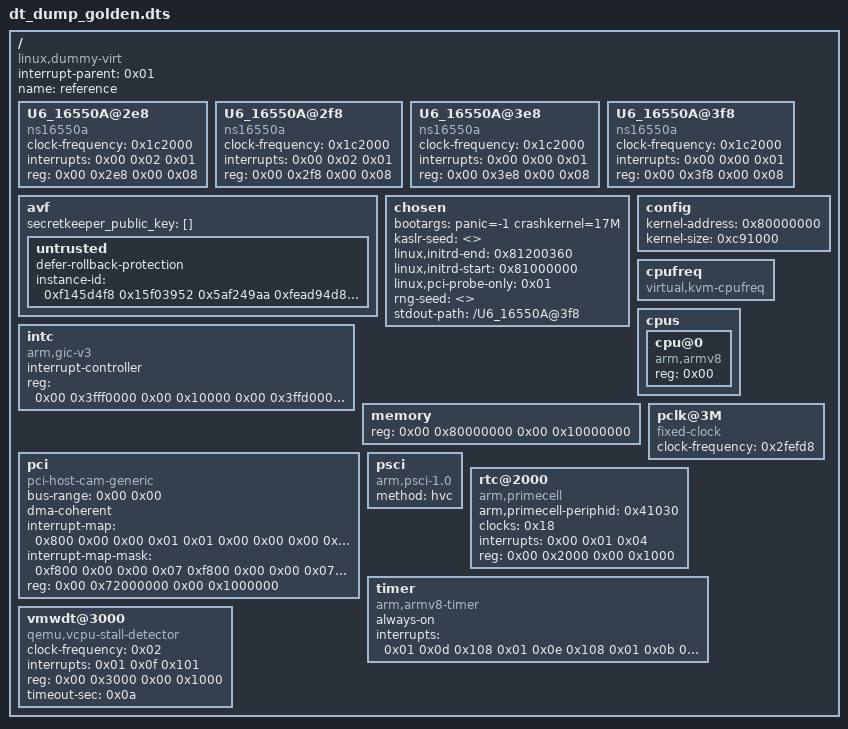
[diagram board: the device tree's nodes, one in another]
/dts-v1/;

/ {
        #address-cells = <0x02>;
        #size-cells = <0x02>;
        compatible = "linux,dummy-virt";
        interrupt-parent = <0x01>;
        name = "reference";

        U6_16550A@2e8 {
                clock-frequency = <0x1c2000>;
                compatible = "ns16550a";
                interrupts = <0x00 0x02 0x01>;
                reg = <0x00 0x2e8 0x00 0x08>;
        };

        U6_16550A@2f8 {
                clock-frequency = <0x1c2000>;
                compatible = "ns16550a";
                interrupts = <0x00 0x02 0x01>;
                reg = <0x00 0x2f8 0x00 0x08>;
        };

        U6_16550A@3e8 {
                clock-frequency = <0x1c2000>;
                compatible = "ns16550a";
                interrupts = <0x00 0x00 0x01>;
                reg = <0x00 0x3e8 0x00 0x08>;
        };

        U6_16550A@3f8 {
                clock-frequency = <0x1c2000>;
                compatible = "ns16550a";
                interrupts = <0x00 0x00 0x01>;
                reg = <0x00 0x3f8 0x00 0x08>;
        };

        __symbols__ {
                intc = "/intc";
        };

        avf {
                secretkeeper_public_key = [];

                untrusted {
                        defer-rollback-protection;
                        instance-id = <0xf145d4f8 0x15f03952 0x5af249aa 0xfead94d8 0xb9f05746 0xd9163f48 0x7251b67b 0xe117409e 0x2b14dfa5 0xcaa8caf7 0x14176d2d 0xf88cc94b 0xeed4a59d 0x9a2d8fe5 0x5ac590f1 0xbb6c96f5>;
                };
        };

        chosen {
                bootargs = "panic=-1 crashkernel=17M";
                kaslr-seed = <>;
                linux,initrd-end = <0x81200360>;
                linux,initrd-start = <0x81000000>;
                linux,pci-probe-only = <0x01>;
                rng-seed = <>;
                stdout-path = "/U6_16550A@3f8";
        };

        config {
                kernel-address = <0x80000000>;
                kernel-size = <0xc91000>;
        };

        cpufreq {
                compatible = "virtual,kvm-cpufreq";
        };

        cpus {
                #address-cells = <0x01>;
                #size-cells = <0x00>;

                cpu@0 {
                        compatible = "arm,armv8";
                        device_type = "cpu";
                        phandle = <0x100>;
                        reg = <0x00>;
                };
        };

        intc {
                #address-cells = <0x02>;
                #interrupt-cells = <0x03>;
                #size-cells = <0x02>;
                compatible = "arm,gic-v3";
                interrupt-controller;
                phandle = <0x01>;
                reg = <0x00 0x3fff0000 0x00 0x10000 0x00 0x3ffd0000 0x00 0x20000>;
        };

        memory {
                device_type = "memory";
                reg = <0x00 0x80000000 0x00 0x10000000>;
        };

        pci {
                #address-cells = <0x03>;
                #interrupt-cells = <0x01>;
                #size-cells = <0x02>;
                bus-range = <0x00 0x00>;
                compatible = "pci-host-cam-generic";
                device_type = "pci";
                dma-coherent;
                interrupt-map = <0x800 0x00 0x00 0x01 0x01 0x00 0x00 0x00 0x04 0x04 0x1000 0x00 0x00 0x01 0x01 0x00 0x00 0x00 0x05 0x04 0x1800 0x00 0x00 0x01 0x01 0x00 0x00 0x00 0x06 0x04 0x2000 0x00 0x00 0x01 0x01 0x00 0x00 0x00 0x07 0x04 0x2800 0x00 0x00 0x01 0x01 0x00 0x00 0x00 0x08 0x04 0x3000 0x00 0x00 0x01 0x01 0x00 0x00 0x00 0x09 0x04 0x3800 0x00 0x00 0x01 0x01 0x00 0x00 0x00 0x0a 0x04 0x4000 0x00 0x00 0x01 0x01 0x00 0x00 0x00 0x0b 0x04 0x4800 0x00 0x00 0x01 0x01 0x00 0x00 0x00 0x0c 0x04>;
                interrupt-map-mask = <0xf800 0x00 0x00 0x07 0xf800 0x00 0x00 0x07 0xf800 0x00 0x00 0x07 0xf800 0x00 0x00 0x07 0xf800 0x00 0x00 0x07 0xf800 0x00 0x00 0x07 0xf800 0x00 0x00 0x07 0xf800 0x00 0x00 0x07 0xf800 0x00 0x00 0x07>;
                ranges = <0x3000000 0x00 0x70000000 0x00 0x70000000 0x00 0x2000000 0x43000000 0x00 0x90800000 0x00 0x90800000 0xff 0x6f800000>;
                reg = <0x00 0x72000000 0x00 0x1000000>;
        };

        pclk@3M {
                #clock-cells = <0x00>;
                clock-frequency = <0x2fefd8>;
                compatible = "fixed-clock";
                phandle = <0x18>;
        };

        psci {
                compatible = "arm,psci-1.0\0arm,psci-0.2";
                method = "hvc";
        };

        rtc@2000 {
                arm,primecell-periphid = <0x41030>;
                clock-names = "apb_pclk";
                clocks = <0x18>;
                compatible = "arm,primecell";
                interrupts = <0x00 0x01 0x04>;
                reg = <0x00 0x2000 0x00 0x1000>;
        };

        timer {
                always-on;
                compatible = "arm,armv8-timer";
                interrupts = <0x01 0x0d 0x108 0x01 0x0e 0x108 0x01 0x0b 0x108 0x01 0x0a 0x108>;
        };

        vmwdt@3000 {
                clock-frequency = <0x02>;
                compatible = "qemu,vcpu-stall-detector";
                interrupts = <0x01 0x0f 0x101>;
                reg = <0x00 0x3000 0x00 0x1000>;
                timeout-sec = <0x0a>;
        };
};
